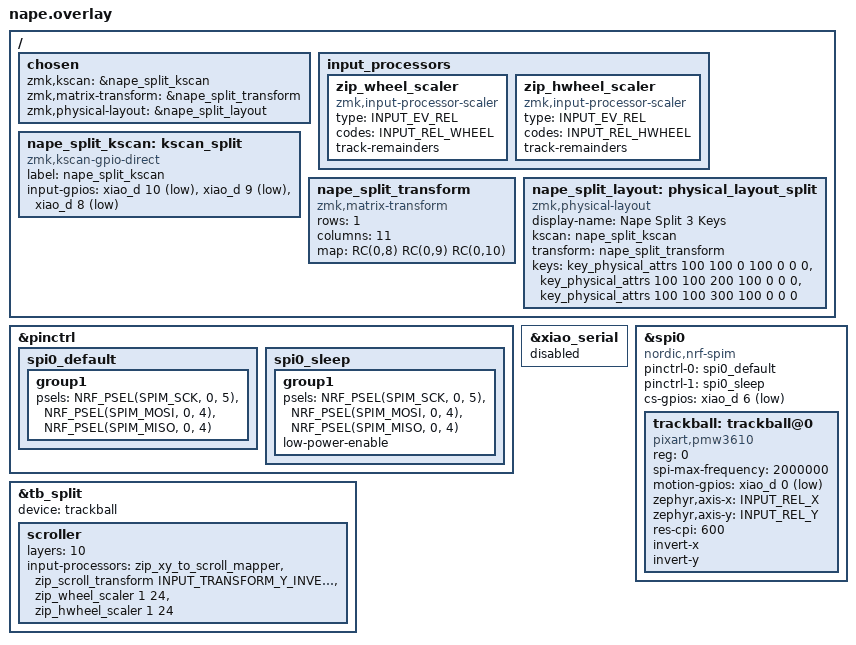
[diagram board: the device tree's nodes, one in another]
#include <dt-bindings/zmk/input_transform.h>
#include <dt-bindings/input/input-event-codes.h>
#include <dt-bindings/zmk/matrix_transform.h>
#include <physical_layouts.dtsi>
#include <input/processors.dtsi>
#include "split_input.dtsi"

/ {
    chosen {
        zmk,kscan = &nape_split_kscan;
        zmk,matrix-transform = &nape_split_transform;
        zmk,physical-layout = &nape_split_layout;
    };

    input_processors {
        zip_wheel_scaler: zip_wheel_scaler {
            compatible = "zmk,input-processor-scaler";
            #input-processor-cells = <2>;
            type = <INPUT_EV_REL>;
            codes = <INPUT_REL_WHEEL>;
            track-remainders;
        };

        zip_hwheel_scaler: zip_hwheel_scaler {
            compatible = "zmk,input-processor-scaler";
            #input-processor-cells = <2>;
            type = <INPUT_EV_REL>;
            codes = <INPUT_REL_HWHEEL>;
            track-remainders;
        };
    };

    /*
     * 単体運用時の6キーkscanは使わず、
     * split統合用に表面3キーだけのkscanを使う
     */
    nape_split_kscan: kscan_split {
        compatible = "zmk,kscan-gpio-direct";
        label = "nape_split_kscan";

        input-gpios =
            <&xiao_d 10 (GPIO_PULL_UP | GPIO_ACTIVE_LOW)>,  // 表面 左キー
            <&xiao_d 9  (GPIO_PULL_UP | GPIO_ACTIVE_LOW)>,  // 表面 中央キー
            <&xiao_d 8  (GPIO_PULL_UP | GPIO_ACTIVE_LOW)>;  // 表面 右キー
    };

    /*
     * FISH全体の matrix は 4x11 を想定。
     * Nape の3キーは末尾3キーとして
     * RC(0,8), RC(0,9), RC(0,10) に流す
     */
    nape_split_transform: nape_split_transform {
        compatible = "zmk,matrix-transform";
        rows = <1>;
        columns = <11>;
        map = <
            RC(0,8) RC(0,9) RC(0,10)
        >;
    };

    /*
     * split用の physical layout
     */
    nape_split_layout: physical_layout_split {
        compatible = "zmk,physical-layout";
        display-name = "Nape Split 3 Keys";
        kscan = <&nape_split_kscan>;
        transform = <&nape_split_transform>;

        keys =
            <&key_physical_attrs 100 100   0   100   0 0 0>,   // 表面 左キー
            <&key_physical_attrs 100 100 200   100   0 0 0>,   // 表面 中央キー
            <&key_physical_attrs 100 100 300   100   0 0 0>;   // 表面 右キー
    };
};

&pinctrl {
    spi0_default: spi0_default {
        group1 {
            psels = <NRF_PSEL(SPIM_SCK, 0, 5)>,
                   <NRF_PSEL(SPIM_MOSI, 0, 4)>,
                   <NRF_PSEL(SPIM_MISO, 0, 4)>;
        };
    };

    spi0_sleep: spi0_sleep {
        group1 {
            psels = <NRF_PSEL(SPIM_SCK, 0, 5)>,
                   <NRF_PSEL(SPIM_MOSI, 0, 4)>,
                   <NRF_PSEL(SPIM_MISO, 0, 4)>;
            low-power-enable;
        };
    };
};

&xiao_serial {
    status = "disabled";
};

&spi0 {
    status = "okay";
    compatible = "nordic,nrf-spim";
    pinctrl-0 = <&spi0_default>;
    pinctrl-1 = <&spi0_sleep>;
    pinctrl-names = "default", "sleep";
    cs-gpios = <&xiao_d 6 (GPIO_ACTIVE_LOW | GPIO_PULL_UP)>;

    trackball: trackball@0 {
        status = "okay";
        compatible = "pixart,pmw3610";
        reg = <0>;
        spi-max-frequency = <2000000>;

        motion-gpios = <&xiao_d 0 (GPIO_ACTIVE_LOW | GPIO_PULL_UP)>;

        zephyr,axis-x = <INPUT_REL_X>;
        zephyr,axis-y = <INPUT_REL_Y>;

        res-cpi = <600>;
        invert-x;
        invert-y;
    };
};

/*
 * トラボの移動/スクロールは split input 経由でドングルへ送る
 */
&tb_split {
    device = <&trackball>;

    scroller {
        layers = <10>;
        input-processors =
            <&zip_xy_to_scroll_mapper>,
            <&zip_scroll_transform INPUT_TRANSFORM_Y_INVERT>,
            <&zip_wheel_scaler 1 24>,
            <&zip_hwheel_scaler 1 24>;
    };
};
